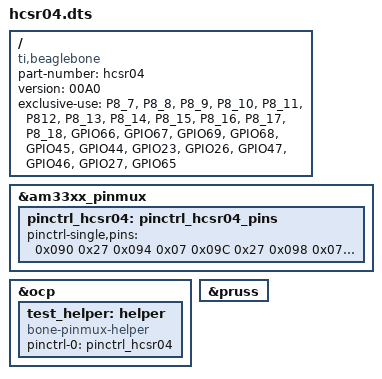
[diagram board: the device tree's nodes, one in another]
/dts-v1/;
/plugin/;

/ {
  compatible = "ti,beaglebone", "ti,beaglebone-black";

  /* identification */
  part-number = "hcsr04";
  version = "00A0";

  exclusive-use =
  "P8_7", "P8_8",
  "P8_9", "P8_10",
  "P8_11", "P812",
  "P8_13", "P8_14",
  "P8_15", "P8_16",
  "P8_17", "P8_18",
  "GPIO66", "GPIO67",
,"GPIO69",	"GPIO68"
,"GPIO45",	"GPIO44"
,"GPIO23"	,"GPIO26"
,"GPIO47"	,"GPIO46"
,"GPIO27"	,"GPIO65";

  fragment@0 {
    target = <&am33xx_pinmux>;
    __overlay__ {
    pinctrl_hcsr04: pinctrl_hcsr04_pins {
        pinctrl-single,pins = <
					/*
						Table of mux options:
						Bit 0 \
						Bit 1 |- Mode
						Bit 2 /
						Bit 3: 1 - Pull disabled, 0 - Pull enabled

						Bit 4: 1 - Pull up, 0 - Pull down
						Bit 5: 1 - Input, 0 – Output
					*/

          0x090 0x27 /* P8_7 gpio1[13] GPIO45 in pulldown Mode: 7 */
          0x094 0x07 /* P8_8 gpio1[12] GPIO44 out pulldown Mode: 7 */

          /*########################## */

          0x09C 0x27 /* P8_9 gpio1[13] GPIO45 in pulldown Mode: 7 */
          0x098 0x07 /* P8_10 gpio1[12] GPIO44 out pulldown Mode: 7 */

          /*########################## */

          0x034 0x27 /* P8_11 gpio1[13] GPIO45 in pulldown Mode: 7 */
          0x030 0x07 /* P8_12 gpio1[12] GPIO44 out pulldown Mode: 7 */

          /*########################## */

          0x024 0x27 /* P8_13 gpio1[13] GPIO45 in pulldown Mode: 7 */
          0x028 0x07 /* P8_14 gpio1[12] GPIO44 out pulldown Mode: 7 */

          /*########################## */

          0x03C 0x27 /* P8_15 gpio1[13] GPIO45 in pulldown Mode: 7 */
          0x038 0x07 /* P8_16 gpio1[12] GPIO44 out pulldown Mode: 7 */

          /*########################## */

          0x02C 0x27 /* P8_17 gpio1[13] GPIO45 in pulldown Mode: 7 */
          0x08C 0x07 /* P8_18 gpio1[12] GPIO44 out pulldown Mode: 7 */

          /*########################## */




          >;
      };
    };
  };

  fragment@1 {
    target = <&ocp>;
    __overlay__ {
      test_helper: helper {
        compatible = "bone-pinmux-helper";
        pinctrl-names = "default";
        pinctrl-0 = <&pinctrl_hcsr04>;
        status = "okay";
      };
    };
  };

  fragment@2{
  target = <&pruss>;
    __overlay__ {
      status = "okay";
    };
  };
};
